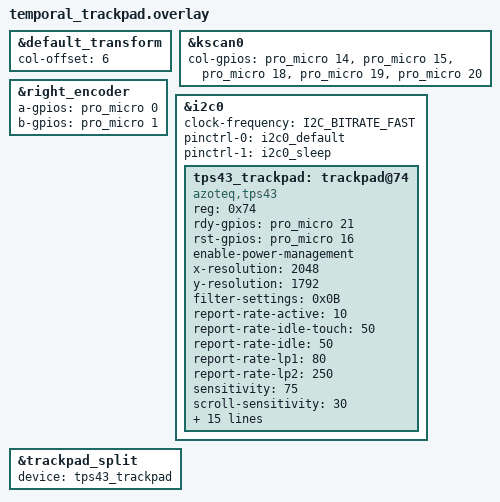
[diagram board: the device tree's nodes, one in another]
/*
 * Copyright (c) 2024 Curtis Bollinger
 *
 * SPDX-License-Identifier: MIT
 */

#include "temporal.dtsi"
#include "temporal_promicro.dtsi"

&default_transform {
    col-offset = <6>;
};

&kscan0 {
    col-gpios
        = <&pro_micro 14 GPIO_ACTIVE_HIGH>  // col_inner
        , <&pro_micro 15 GPIO_ACTIVE_HIGH>  // col_index
        , <&pro_micro 18 GPIO_ACTIVE_HIGH>  // col_middle
        , <&pro_micro 19 GPIO_ACTIVE_HIGH>  // col_ring
        , <&pro_micro 20 GPIO_ACTIVE_HIGH>  // col_pinky (also encoder switch)

        // I need this pin for the trackpad
        //, <&pro_micro 21 GPIO_ACTIVE_HIGH>  // col_extra
        ;
};

&right_encoder {
    a-gpios = <&pro_micro 0 (GPIO_ACTIVE_HIGH | GPIO_PULL_UP)>; // P0.08 = Encoder Pin B
    b-gpios = <&pro_micro 1 (GPIO_ACTIVE_HIGH | GPIO_PULL_UP)>; // P0.06 = Encoder Pin A
    status = "okay";
};

/*
 * Azoteq Trackpad Configuration
 *
 * decided to use the the geeksville module
 * README: https://github.com/geeksville/zmk_driver_azoteq
 *
 * Beekeeb Toucan 2 is an example implementation, but note it uses a seeed xiao
 * which has different i2c pins than the nice_nano. The Toucan 2 does not have a
 * dongle, but it uses right side trackpad
 * beekeeb/zmk-keyboard-toucan2/boards/shields/toucan/toucan_right.overlay
 *
 * This Temporal will use the default i2c pins as defined in zmk
 * zmkfirmware/zmk/app/module/boards/nicekeyboards/nice_nano/nice_nano-pinctrl.dtsi
 *
 * C:\Repo\temp\zmk_driver_azoteq\dts\bindings\input\azoteq,tps43-common.yaml
 *
 */

trackpad: &i2c0 {
    status = "okay";
    clock-frequency = <I2C_BITRATE_FAST>;
    pinctrl-0 = <&i2c0_default>;
    pinctrl-1 = <&i2c0_sleep>;
    pinctrl-names = "default", "sleep";

    tps43_trackpad: trackpad@74 {
        compatible = "azoteq,tps43";
        reg = <0x74>;
        status = "okay";

        rdy-gpios = <&pro_micro 21 GPIO_ACTIVE_HIGH>;
        rst-gpios = <&pro_micro 16 GPIO_ACTIVE_HIGH>;

        enable-power-management;

        /* from TPS43 datasheet */
        x-resolution = <2048>;
        y-resolution = <1792>;

        filter-settings = <0x0B>;

        report-rate-active = <10>;
        report-rate-idle-touch = <50>;
        report-rate-idle = <50>;
        report-rate-lp1 = <80>;
        report-rate-lp2 = <250>;

        sensitivity = <75>;            /* default 100 */
        scroll-sensitivity = <30>;     /* default 50 */
        zoom-sensitivity = <45>;       /* default 100 */

        tap-time = <150>;
        tap-distance = <15>;
        hold-time = <1200>;

        scroll-initial-distance = <50>;

        zoom-initial-distance = <50>;
        zoom-consecutive-distance = <25>;

        zoom;
        scroll;
        two-finger-tap;
        single-tap;
        //press-and-hold;
        //three-finger-swipe;
        //three-finger-swipe-throttle-ms = <800>;

        switch-xy;
        invert-x;
        invert-y;
        invert-scroll-x;
    };
};

&trackpad_split {
    device = <&tps43_trackpad>;
    status = "okay";
};


